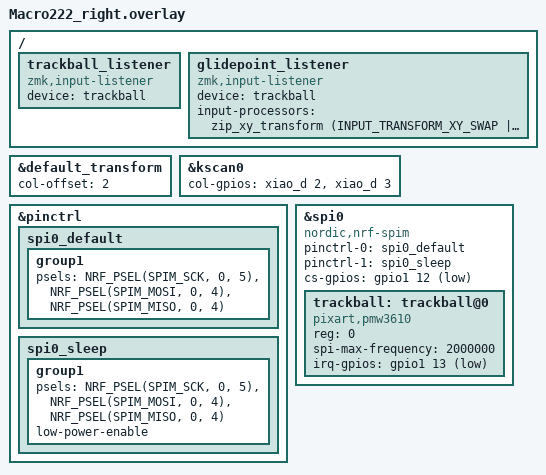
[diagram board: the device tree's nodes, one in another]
#include "Macro222.dtsi" // The shared dtsi file is included in the overlay
#include <dt-bindings/zmk/input_transform.h>


// matrix transformでのピン数オフセット
&default_transform { // Offset of 2 because the left side has 2 columns
    col-offset = <2>;
};

// kscan
&kscan0 {
    col-gpios
        = <&xiao_d 2 GPIO_ACTIVE_HIGH>
        , <&xiao_d 3 GPIO_ACTIVE_HIGH>
        ;
};

// pmw-3610-driverを動かすコード----------------------------------
&pinctrl {
    spi0_default: spi0_default {
        group1 {
            psels = <NRF_PSEL(SPIM_SCK, 0, 5)>,
                <NRF_PSEL(SPIM_MOSI, 0, 4)>,
                <NRF_PSEL(SPIM_MISO, 0, 4)>;
        };
    };

    spi0_sleep: spi0_sleep {
        group1 {
            psels = <NRF_PSEL(SPIM_SCK, 0, 5)>,
                <NRF_PSEL(SPIM_MOSI, 0, 4)>,
                <NRF_PSEL(SPIM_MISO, 0, 4)>;
            low-power-enable;
        };
    };
};

&spi0 {
    status = "okay";
    compatible = "nordic,nrf-spim";
    pinctrl-0 = <&spi0_default>;
    pinctrl-1 = <&spi0_sleep>;
    pinctrl-names = "default", "sleep";
    cs-gpios = <&gpio1 12 GPIO_ACTIVE_LOW>; // CS

    trackball: trackball@0 {
        status = "okay";
        compatible = "pixart,pmw3610";
        reg = <0>;
        spi-max-frequency = <2000000>;
        irq-gpios = <&gpio1 13 (GPIO_ACTIVE_LOW | GPIO_PULL_UP)>; // MOTION

        /*   optional features   */
        // snipe-layers = <1>;
        // scroll-layers = <2 3>;
        // automouse-layer = <4>;
    };
};

/ {
  trackball_listener {
    compatible = "zmk,input-listener";
    device = <&trackball>;
  };
};

// センサーの向きを変更するためのinput processors
/ {
    glidepoint_listener {
        compatible = "zmk,input-listener";
        device = <&trackball>;
        input-processors = <&zip_xy_transform (INPUT_TRANSFORM_XY_SWAP | INPUT_TRANSFORM_X_INVERT | INPUT_TRANSFORM_Y_INVERT)>;
    };
};
//-------------------------------------------------------------------
